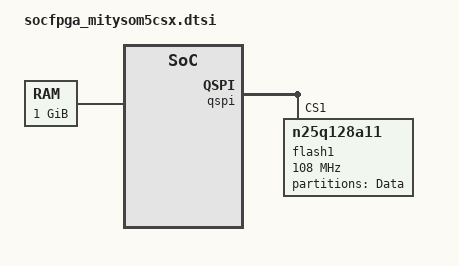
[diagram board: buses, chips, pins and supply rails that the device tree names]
#include "socfpga_mitysom5cs.dtsi"

/{
	memory {
		name = "memory";
		device_type = "memory";
		reg = <0x0 0x40000000>; /* 1 GB  */
	};
};

&qspi {
	flash1: nor@1 {
		#address-cells = <1>;
		#size-cells = <1>;
		compatible = "n25q128a11", "jedec,spi-nor";
		reg = <1>;      /* chip select */
		spi-max-frequency = <108000000>;
		m25p,fast-read;
		page-size = <256>;
		block-size = <16>; /* 2^16, 64KB */
		cdns,read-delay = <4>;  /* delay value in read data capture register */
		cdns,tshsl-ns = <50>;
		cdns,tsd2d-ns = <50>;
		cdns,tchsh-ns = <4>;
		cdns,tslch-ns = <4>;
		partition@0 {
			/* 16MB for raw data. */
			label = "Data";
			reg = <0x0 0x1000000>;
		};
	};
};
